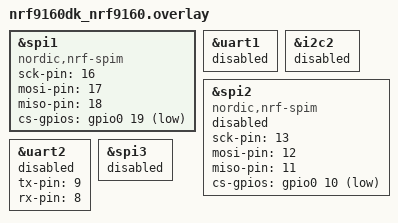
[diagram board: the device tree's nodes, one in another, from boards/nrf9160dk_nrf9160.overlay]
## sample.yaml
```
sample:
  name: nrfx Peripheral Resource Sharing example
tests:
  sample.boards.nrf.nrfx_prs:
    platform_allow: nrf9160dk_nrf9160 nrf5340dk_nrf5340_cpuapp
    tags: board
    harness: console
    harness_config:
      type: multi_line
      ordered: true
      regex:
        - "nrfx PRS example"
```

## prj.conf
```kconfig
CONFIG_NRFX_PRS_BOX_2=y
CONFIG_NRFX_SPIM2=y
CONFIG_NRFX_UARTE2=y

CONFIG_SPI=y
```

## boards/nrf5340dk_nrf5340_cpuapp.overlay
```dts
&spi1 {
	compatible = "nordic,nrf-spim";
	status = "okay";
	sck-pin = <6>;
	mosi-pin = <7>;
	miso-pin = <25>;
	cs-gpios = <&gpio0 26 GPIO_ACTIVE_LOW>;
};

&uart1 {
	status = "disabled";
};

&spi2 {
	compatible = "nordic,nrf-spim";
	status = "disabled";
	sck-pin = <41>;
	mosi-pin = <40>;
	miso-pin = <39>;
	cs-gpios = <&gpio1 6 GPIO_ACTIVE_LOW>;
};

&uart2 {
	status = "disabled";
	tx-pin = <43>;
	rx-pin = <42>;
};
```

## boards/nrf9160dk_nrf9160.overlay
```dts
&spi1 {
	compatible = "nordic,nrf-spim";
	status = "okay";
	sck-pin = <16>;
	mosi-pin = <17>;
	miso-pin = <18>;
	cs-gpios = <&gpio0 19 GPIO_ACTIVE_LOW>;
};

&uart1 {
	status = "disabled";
};

&i2c2 {
	status = "disabled";
};

&spi2 {
	compatible = "nordic,nrf-spim";
	status = "disabled";
	sck-pin = <13>;
	mosi-pin = <12>;
	miso-pin = <11>;
	cs-gpios = <&gpio0 10 GPIO_ACTIVE_LOW>;
};

&uart2 {
	status = "disabled";
	tx-pin = <9>;
	rx-pin = <8>;
};

&spi3 {
	status = "disabled";
};
```

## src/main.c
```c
/*
 * Copyright (c) 2021 Nordic Semiconductor ASA
 *
 * SPDX-License-Identifier: Apache-2.0
 */

#include <zephyr.h>

#include <drivers/src/prs/nrfx_prs.h>
#include <nrfx_spim.h>
#include <nrfx_uarte.h>
#include <drivers/gpio.h>
#include <drivers/spi.h>

#define TRANSFER_LENGTH 10

/* DT node corresponding to peripheral (SPIM1) used via Zephyr SPI driver. */
#define SPI_DEV_NODE DT_NODELABEL(spi1)

/* DT nodes corresponding to peripherals (SPIM2 and UARTE2) used directly via
 * nrfx drivers.
 */
#define SPIM_NODE  DT_NODELABEL(spi2)
#define UARTE_NODE DT_NODELABEL(uart2)

static nrfx_spim_t spim = NRFX_SPIM_INSTANCE(2);
static nrfx_uarte_t uarte = NRFX_UARTE_INSTANCE(2);
static bool spim_initialized;
static bool uarte_initialized;
static volatile size_t received;

static enum {
	PERFORM_TRANSFER,
	SWITCH_PERIPHERAL
} command;
static K_SEM_DEFINE(button_pressed, 0, 1);
static K_SEM_DEFINE(transfer_finished, 0, 1);

static void sw0_handler(const struct device *dev, struct gpio_callback *cb,
			uint32_t pins)
{
	command = PERFORM_TRANSFER;
	k_sem_give(&button_pressed);
}

static void sw1_handler(const struct device *dev, struct gpio_callback *cb,
			uint32_t pins)
{
	command = SWITCH_PERIPHERAL;
	k_sem_give(&button_pressed);
}

static bool init_buttons(void)
{
	static const struct button_spec {
		struct gpio_dt_spec gpio;
		char const *label;
		char const *action;
		gpio_callback_handler_t handler;
	} btn_spec[] = {
		{
			GPIO_DT_SPEC_GET(DT_ALIAS(sw0), gpios),
			DT_PROP(DT_ALIAS(sw0), label),
			"trigger a transfer",
			sw0_handler
		},
		{
			GPIO_DT_SPEC_GET(DT_ALIAS(sw1), gpios),
			DT_PROP(DT_ALIAS(sw1), label),
			"switch the type of peripheral",
			sw1_handler
		},
	};
	static struct gpio_callback btn_cb_data[ARRAY_SIZE(btn_spec)];

	for (int i = 0; i < ARRAY_SIZE(btn_spec); ++i) {
		const struct button_spec *btn = &btn_spec[i];
		int ret;

		if (!device_is_ready(btn->gpio.port)) {
			printk("%s is not ready\n", btn->gpio.port->name);
			return false;
		}

		ret = gpio_pin_configure_dt(&btn->gpio, GPIO_INPUT);
		if (ret < 0) {
			printk("Failed to configure %s pin %d: %d\n",
				btn->gpio.port->name, btn->gpio.pin, ret);
			return false;
		}

		ret = gpio_pin_interrupt_configure_dt(&btn->gpio,
						      GPIO_INT_EDGE_TO_ACTIVE);
		if (ret < 0) {
			printk("Failed to configure interrupt on %s pin %d: %d\n",
				btn->gpio.port->name, btn->gpio.pin, ret);
			return false;
		}

		gpio_init_callback(&btn_cb_data[i],
				   btn->handler, BIT(btn->gpio.pin));
		gpio_add_callback(btn->gpio.port, &btn_cb_data[i]);
		printk("-> press \"%s\" to %s\n", btn->label, btn->action);
	}

	return true;
}

static void spim_handler(const nrfx_spim_evt_t *p_event, void *p_context)
{
	if (p_event->type == NRFX_SPIM_EVENT_DONE) {
		k_sem_give(&transfer_finished);
	}
}

static bool switch_to_spim(void)
{
	if (spim_initialized) {
		return true;
	}

	if (uarte_initialized) {
		nrfx_uarte_uninit(&uarte);
		uarte_initialized = false;
	}

	nrfx_err_t err;
	nrfx_spim_config_t spim_config = NRFX_SPIM_DEFAULT_CONFIG(
		DT_PROP(SPIM_NODE, sck_pin),
		DT_PROP(SPIM_NODE, mosi_pin),
		DT_PROP(SPIM_NODE, miso_pin),
		NRF_DT_GPIOS_TO_PSEL(SPIM_NODE, cs_gpios));
	spim_config.frequency = NRF_SPIM_FREQ_1M;

	err = nrfx_spim_init(&spim, &spim_config, spim_handler, NULL);
	if (err != NRFX_SUCCESS) {
		printk("nrfx_spim_init() failed: 0x%08x\n", err);
		return false;
	}

	spim_initialized = true;
	printk("Switched to SPIM\n");
	return true;
}

static bool spim_transfer(const uint8_t *tx_data, size_t tx_data_len,
			  uint8_t *rx_buf, size_t rx_buf_size)
{
	nrfx_err_t err;
	nrfx_spim_xfer_desc_t xfer_desc = {
		.p_tx_buffer = tx_data,
		.tx_length = tx_data_len,
		.p_rx_buffer = rx_buf,
		.rx_length = rx_buf_size,
	};

	err = nrfx_spim_xfer(&spim, &xfer_desc, 0);
	if (err != NRFX_SUCCESS) {
		printk("nrfx_spim_xfer() failed: 0x%08x\n", err);
		return false;
	}

	if (k_sem_take(&transfer_finished, K_MSEC(100)) != 0) {
		printk("SPIM transfer timeout\n");
		return false;
	}

	received = rx_buf_size;
	return true;
}

static void uarte_handler(const nrfx_uarte_event_t *p_event, void *p_context)
{
	if (p_event->type == NRFX_UARTE_EVT_RX_DONE) {
		received = p_event->data.rxtx.bytes;
		k_sem_give(&transfer_finished);
	} else if (p_event->type == NRFX_UARTE_EVT_ERROR) {
		received = 0;
		k_sem_give(&transfer_finished);
	}
}

static bool switch_to_uarte(void)
{
	if (uarte_initialized) {
		return true;
	}

	if (spim_initialized) {
		nrfx_spim_uninit(&spim);
		spim_initialized = false;
	}

	nrfx_err_t err;
	nrfx_uarte_config_t uarte_config = NRFX_UARTE_DEFAULT_CONFIG(
		DT_PROP(UARTE_NODE, tx_pin),
		DT_PROP(UARTE_NODE, rx_pin));
	uarte_config.baudrate = NRF_UARTE_BAUDRATE_1000000;

	err = nrfx_uarte_init(&uarte, &uarte_config, uarte_handler);
	if (err != NRFX_SUCCESS) {
		printk("nrfx_uarte_init() failed: 0x%08x\n", err);
		return false;
	}

	uarte_initialized = true;
	printk("Switched to UARTE\n");
	return true;
}

static bool uarte_transfer(const uint8_t *tx_data, size_t tx_data_len,
			   uint8_t *rx_buf, size_t rx_buf_size)
{
	nrfx_err_t err;

	err = nrfx_uarte_rx(&uarte, rx_buf, rx_buf_size);
	if (err != NRFX_SUCCESS) {
		printk("nrfx_uarte_rx() failed: 0x%08x\n", err);
		return false;
	}

	err = nrfx_uarte_tx(&uarte, tx_data, tx_data_len);
	if (err != NRFX_SUCCESS) {
		printk("nrfx_uarte_tx() failed: 0x%08x\n", err);
		return false;
	}

	if (k_sem_take(&transfer_finished, K_MSEC(100)) != 0) {
		nrfx_uarte_rx_abort(&uarte);

		if (k_sem_take(&transfer_finished, K_MSEC(10)) != 0) {
			printk("UARTE transfer timeout\n");
			return false;
		}
	}

	return true;
}

static void buffer_dump(const uint8_t *buffer, size_t length)
{
	for (int i = 0; i < length; ++i) {
		printk(" %02X", buffer[i]);
	}
	printk("\n");
}

static bool spi_dev_transfer(const struct device* spi_dev)
{
	static const uint8_t tx_buffer[] = "Nordic Semiconductor";
	static uint8_t rx_buffer[sizeof(tx_buffer)];
	static const struct spi_cs_control spi_dev_cs_ctrl = {
		.gpio_dev = DEVICE_DT_GET(DT_GPIO_CTLR(SPI_DEV_NODE, cs_gpios)),
		.gpio_pin = DT_GPIO_PIN(SPI_DEV_NODE, cs_gpios),
		.gpio_dt_flags = DT_GPIO_FLAGS(SPI_DEV_NODE, cs_gpios)
	};
	static const struct spi_config spi_dev_cfg = {
		.operation = SPI_OP_MODE_MASTER | SPI_WORD_SET(8) |
			     SPI_TRANSFER_MSB,
		.frequency = 1000000,
		.cs = &spi_dev_cs_ctrl
	};
	static const struct spi_buf tx_buf = {
		.buf = (void *)tx_buffer,
		.len = sizeof(tx_buffer)
	};
	static const struct spi_buf_set tx = {
		.buffers = &tx_buf,
		.count = 1
	};
	static const struct spi_buf rx_buf = {
		.buf = rx_buffer,
		.len = sizeof(rx_buffer),
	};
	static const struct spi_buf_set rx = {
		.buffers = &rx_buf,
		.count = 1
	};
	int ret;

	printk("-- Background transfer on \"%s\" --\n", spi_dev->name);

	ret = spi_transceive(spi_dev, &spi_dev_cfg, &tx, &rx);
	if (ret < 0) {
		printk("Background transfer failed: %d\n", ret);
		return false;
	}

	printk("Tx:");
	buffer_dump(tx_buf.buf, tx_buf.len);
	printk("Rx:");
	buffer_dump(rx_buf.buf, rx_buf.len);
	return true;
}

void main(void)
{
	printk("nrfx PRS example on %s\n", CONFIG_BOARD);

	static uint8_t tx_buffer[TRANSFER_LENGTH];
	static uint8_t rx_buffer[sizeof(tx_buffer)];
	uint8_t fill_value = 0;
	const struct device* spi_dev = DEVICE_DT_GET(SPI_DEV_NODE);

	if (!device_is_ready(spi_dev)) {
		printk("%s is not ready\n", spi_dev->name);
		return;
	}

	/* Install handler for the interrupt shared between SPIM2 and UARTE2. */
	IRQ_CONNECT(DT_IRQN(DT_NODELABEL(spi2)),
		    DT_IRQ(DT_NODELABEL(spi2), priority),
		    nrfx_isr, nrfx_prs_box_2_irq_handler, 0);

	if (!init_buttons()) {
		return;
	}

	if (!switch_to_spim()) {
		return;
	}

	for (;;) {
		if (k_sem_take(&button_pressed, K_MSEC(5000)) == 0) {
			bool res;

			switch (command) {
			case PERFORM_TRANSFER:
				printk("-- %s transfer --\n",
					spim_initialized ? "SPIM" : "UARTE");
				received = 0;
				for (int i = 0; i < sizeof(tx_buffer); ++i) {
					tx_buffer[i] = fill_value++;
				}
				res = (spim_initialized
				       ? spim_transfer(tx_buffer,
						       sizeof(tx_buffer),
						       rx_buffer,
						       sizeof(rx_buffer))
				       : uarte_transfer(tx_buffer,
							sizeof(tx_buffer),
							rx_buffer,
							sizeof(rx_buffer)));
				if (!res) {
					return;
				}

				printk("Tx:");
				buffer_dump(tx_buffer, sizeof(tx_buffer));
				printk("Rx:");
				buffer_dump(rx_buffer, received);
				break;

			case SWITCH_PERIPHERAL:
				res = (spim_initialized
				       ? switch_to_uarte()
				       : switch_to_spim());
				if (!res) {
					return;
				}
				break;
			}
		} else {
			if (!spi_dev_transfer(spi_dev)) {
				return;
			}
		}
	}
}
```
